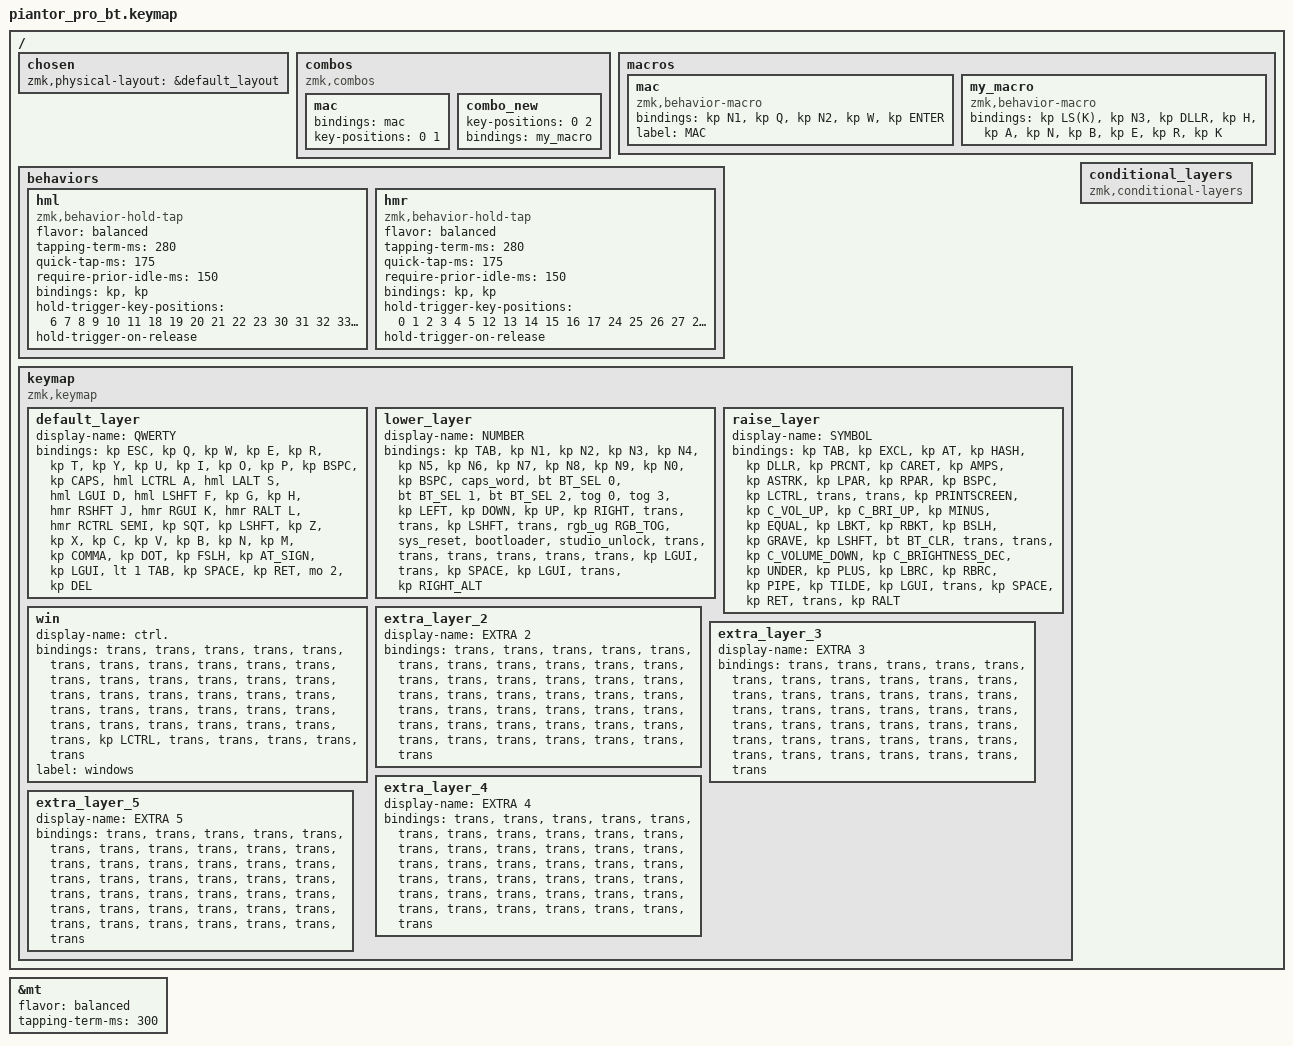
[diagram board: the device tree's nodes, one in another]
/*
 * Copyright (c) 2020 The ZMK Contributors
 *
 * SPDX-License-Identifier: MIT
 */

#include <behaviors.dtsi>
#include <dt-bindings/zmk/bt.h>
#include <dt-bindings/zmk/keys.h>
#include <dt-bindings/zmk/rgb.h>

&mt {
    flavor = "balanced";
    tapping-term-ms = <300>;
};

/ {
    chosen { zmk,physical-layout = &default_layout; };
};

/ {
    combos {
        compatible = "zmk,combos";

        mac {
            bindings = <&mac>;
            key-positions = <0 1>;
        };

        combo_new {
            key-positions = <0 2>;
            bindings = <&my_macro>;
        };
    };

    macros {
        mac: mac {
            compatible = "zmk,behavior-macro";
            #binding-cells = <0>;
            bindings = <&kp N1 &kp Q &kp N2 &kp W &kp ENTER>;
            label = "MAC";
        };

        my_macro: my_macro {
            compatible = "zmk,behavior-macro";
            #binding-cells = <0>;
            bindings = <&kp LS(K) &kp N3 &kp DLLR &kp H &kp A &kp N &kp B &kp E &kp R &kp K>;
        };
    };

    behaviors {
        hml: hml {
            compatible = "zmk,behavior-hold-tap";
            #binding-cells = <2>;
            flavor = "balanced";
            tapping-term-ms = <280>;
            quick-tap-ms = <175>;
            require-prior-idle-ms = <150>;
            bindings = <&kp>, <&kp>;
            hold-trigger-key-positions = <6 7 8 9 10 11 18 19 20 21 22 23 30 31 32 33 34 35 36 37 38 39 40 41>;
            hold-trigger-on-release;
        };

        hmr: hmr {
            compatible = "zmk,behavior-hold-tap";
            #binding-cells = <2>;
            flavor = "balanced";
            tapping-term-ms = <280>;
            quick-tap-ms = <175>;
            require-prior-idle-ms = <150>;
            bindings = <&kp>, <&kp>;
            hold-trigger-key-positions = <0 1 2 3 4 5 12 13 14 15 16 17 24 25 26 27 28 29 36 37 38 39 40 41>;
            hold-trigger-on-release;
        };
    };

    keymap {
        compatible = "zmk,keymap";

        default_layer {
            display-name = "QWERTY";

            // --------------------------------------------------------------------------------
            // |  TAB |  Q  |  W  |  E  |  R  |  T  |  Y  |  U   |  I  |  O  |  P  | BSPC |
            // | CTRL |  A  |  S  |  D  |  F  |  G  |  H  |  J   |  K  |  L  |  ;  |  '   |
            // | SHFT |  Z  |  X  |  C  |  V  |  B  |  N  |  M   |  ,  |  .  |  /  | ESC  |
            //                    | GUI | LWR | SPC | ENT | RSE  | ALT |

            bindings = <
&kp ESC  &kp Q  &kp W  &kp E  &kp R  &kp T  &kp Y  &kp U  &kp I  &kp O  &kp P  &kp BSPC  &kp CAPS  &hml LCTRL A  &hml LALT S  &hml LGUI D  &hml LSHFT F  &kp G  &kp H  &hmr RSHFT J  &hmr RGUI K  &hmr RALT L  &hmr RCTRL SEMI  &kp SQT  &kp LSHFT  &kp Z  &kp X  &kp C  &kp V  &kp B  &kp N  &kp M  &kp COMMA  &kp DOT  &kp FSLH  &kp AT_SIGN  &kp LGUI  &lt 1 TAB  &kp SPACE  &kp RET  &mo 2  &kp DEL
            >;
        };

        lower_layer {
            display-name = "NUMBER";

            // -----------------------------------------------------------------------------------------
            // |  TAB |  1  |  2  |  3  |  4  |  5    |  6  |  7  |  8  |  9  |  0  | BSPC |
            // | CTRL | BT1 | BT2 | BT3 | BT4 | BT5   | LFT | DWN |  UP | RGT |     |      |
            // | SHFT | BTCR| RGB | RST | BOOT| Unlock|     |     |     |     |     |      |
            //                    | GUI |     | SPC   | ENT |     | ALT |

            bindings = <
&kp TAB  &kp N1  &kp N2  &kp N3  &kp N4  &kp N5  &kp N6  &kp N7  &kp N8  &kp N9  &kp N0  &kp BSPC  &caps_word  &bt BT_SEL 0  &bt BT_SEL 1  &bt BT_SEL 2  &tog 0  &tog 3  &kp LEFT  &kp DOWN  &kp UP  &kp RIGHT  &trans  &trans  &kp LSHFT  &trans  &rgb_ug RGB_TOG  &sys_reset  &bootloader  &studio_unlock  &trans  &trans  &trans  &trans  &trans  &trans  &kp LGUI  &trans  &kp SPACE  &kp LGUI  &trans  &kp RIGHT_ALT
            >;
        };

        raise_layer {
            display-name = "SYMBOL";

            // -----------------------------------------------------------------------------------------
            // |  TAB |  !  |  @  |  #  |  $  |  %  |  ^  |  &  |  *  |  (  |  )  | BSPC |
            // | CTRL |     |     |     |     |     |  -  |  =  |  [  |  ]  |  \  |  `   |
            // | SHFT |     |     |     |     |     |  _  |  +  |  {  |  }  | "|" |  ~   |
            //                    | GUI |     | SPC | ENT |     | ALT |

            bindings = <
&kp TAB  &kp EXCL  &kp AT  &kp HASH  &kp DLLR  &kp PRCNT  &kp CARET  &kp AMPS  &kp ASTRK  &kp LPAR  &kp RPAR  &kp BSPC  &kp LCTRL  &trans  &trans  &kp PRINTSCREEN  &kp C_VOL_UP  &kp C_BRI_UP  &kp MINUS  &kp EQUAL  &kp LBKT  &kp RBKT  &kp BSLH  &kp GRAVE  &kp LSHFT  &bt BT_CLR  &trans  &trans  &kp C_VOLUME_DOWN  &kp C_BRIGHTNESS_DEC  &kp UNDER  &kp PLUS  &kp LBRC  &kp RBRC  &kp PIPE  &kp TILDE  &kp LGUI  &trans  &kp SPACE  &kp RET  &trans  &kp RALT
            >;
        };

        win {
            display-name = "ctrl.";
            bindings = <
&trans  &trans  &trans  &trans  &trans  &trans  &trans  &trans  &trans  &trans  &trans  &trans  &trans  &trans  &trans  &trans  &trans  &trans  &trans  &trans  &trans  &trans  &trans  &trans  &trans  &trans  &trans  &trans  &trans  &trans  &trans  &trans  &trans  &trans  &trans  &trans  &kp LCTRL  &trans  &trans  &trans  &trans  &trans
            >;

            label = "windows";
        };

        extra_layer_2 {
            display-name = "EXTRA 2";
            bindings = <
&trans  &trans  &trans  &trans  &trans  &trans  &trans  &trans  &trans  &trans  &trans  &trans  &trans  &trans  &trans  &trans  &trans  &trans  &trans  &trans  &trans  &trans  &trans  &trans  &trans  &trans  &trans  &trans  &trans  &trans  &trans  &trans  &trans  &trans  &trans  &trans  &trans  &trans  &trans  &trans  &trans  &trans
            >;
        };

        extra_layer_3 {
            display-name = "EXTRA 3";
            bindings = <
&trans  &trans  &trans  &trans  &trans  &trans  &trans  &trans  &trans  &trans  &trans  &trans  &trans  &trans  &trans  &trans  &trans  &trans  &trans  &trans  &trans  &trans  &trans  &trans  &trans  &trans  &trans  &trans  &trans  &trans  &trans  &trans  &trans  &trans  &trans  &trans  &trans  &trans  &trans  &trans  &trans  &trans
            >;
        };

        extra_layer_4 {
            display-name = "EXTRA 4";
            bindings = <
&trans  &trans  &trans  &trans  &trans  &trans  &trans  &trans  &trans  &trans  &trans  &trans  &trans  &trans  &trans  &trans  &trans  &trans  &trans  &trans  &trans  &trans  &trans  &trans  &trans  &trans  &trans  &trans  &trans  &trans  &trans  &trans  &trans  &trans  &trans  &trans  &trans  &trans  &trans  &trans  &trans  &trans
            >;
        };

        extra_layer_5 {
            display-name = "EXTRA 5";
            bindings = <
&trans  &trans  &trans  &trans  &trans  &trans  &trans  &trans  &trans  &trans  &trans  &trans  &trans  &trans  &trans  &trans  &trans  &trans  &trans  &trans  &trans  &trans  &trans  &trans  &trans  &trans  &trans  &trans  &trans  &trans  &trans  &trans  &trans  &trans  &trans  &trans  &trans  &trans  &trans  &trans  &trans  &trans
            >;
        };
    };

    conditional_layers { compatible = "zmk,conditional-layers"; };
};
